# CLK1_RATE_ADAPT_RESP_32TO128_CLK1 register map
Vendor: Texas Instruments
Peripheral module from a debugger description file (folder omap4430).
Registers are 32-bit, read-only, reset 0x2D0001 unless marked. A register's access mark holds for its fields unless they carry their own. Offsets are as the file gives them; lines under a group give offsets from that group; [hi:lo] are bit positions; {n}, {i} and the like mark numbered series; 'fields as' and 'values as' point back to an identical list; <NAME> marks a mode.

## CLK1_RATE_ADAPT_RESP_32TO128_CLK1
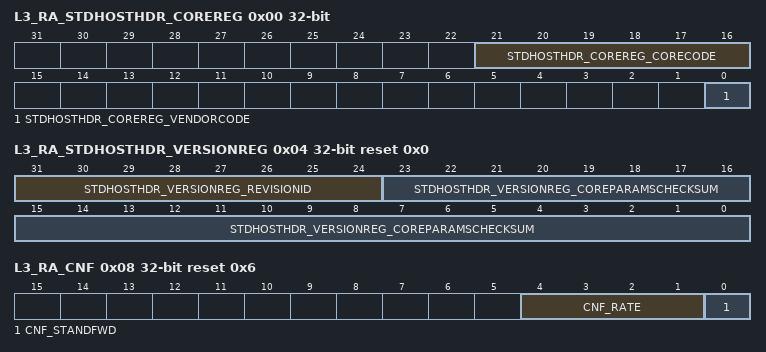
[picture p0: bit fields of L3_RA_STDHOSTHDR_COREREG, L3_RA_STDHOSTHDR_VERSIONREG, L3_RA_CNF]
0x00 L3_RA_STDHOSTHDR_COREREG
  [21:16] STDHOSTHDR_COREREG_CORECODE — The Core Code field is a constant reporting a vendor-specific core generator code. Type: Constant. Reset value: 0x2D.
  [0] STDHOSTHDR_COREREG_VENDORCODE — The Vendor Code field is a constant reporting the core generator vendor code. Type: Constant. Reset value: 0x1.
    0=STDHOSTHDR_COREREG_VENDORCODE_0_r (Third-party vendor.); 1=STDHOSTHDR_COREREG_VENDORCODE_1_r
0x04 L3_RA_STDHOSTHDR_VERSIONREG reset 0x0
  [31:24] STDHOSTHDR_VERSIONREG_REVISIONID — The Revision Identifier field is a constant reporting the core generator revision number. Type: Constant. Reset value: 0x0.
  [23:0] STDHOSTHDR_VERSIONREG_COREPARAMSCHECKSUM — Reserved. Type: Reserved. Reset value: Reserved.
0x08 L3_RA_CNF access per field reset 0x6
  [4:1] CNF_RATE rw — Indicates the throughput ratio between input and output (Rate = [16 x (Incoming_Throughput/Outgoing_Throuput)] - 1), when bit StAndFwd bit is reset. Ignored when StAndFwd bit is set. Type: Control. Reset value: 0x3.
  [0] CNF_STANDFWD rw — When this bit is set, the Packet Transport Unit stores the entire NTTP packet, then forwards it on TX port. Type: Control. Reset value: 0x0.
